AUTOSAR XML (schema 4-2-2)
package /pkg_intf
  sender receiver interface if_voltage
    data voltage: type=adt_voltage
  sender receiver interface if_duty
    data duty: type=adt_duty
package /pkg_led
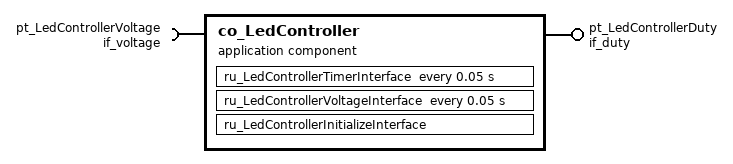
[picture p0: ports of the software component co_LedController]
  application sw component type co_LedController
    provide port pt_LedControllerDuty: provided-interface=if_duty
    require port pt_LedControllerVoltage: required-interface=if_voltage
    behavior IB_co_LedController: data-type-mapping=DTMS_DataTypeMappingSet, handle-termination-and-restart=NO-SUPPORT
      timing event TE_50ms: start-on-event=ru_LedControllerTimerInterface, period=0.05
      timing event TE_50ms: start-on-event=ru_LedControllerVoltageInterface, period=0.05
      runnable ru_LedControllerTimerInterface
        data-read-access:
          access calcDuty
        data-write-access:
          access dsp_LedControllerDuty: accessed-variable=pt_LedControllerDuty.duty
      runnable ru_LedControllerInitializeInterface
        data-write-access:
          access initDuty
      runnable ru_LedControllerVoltageInterface
        data-read-access:
          access drp_LedControllerVoltage: accessed-variable=pt_LedControllerVoltage.voltage
        data-write-access:
          access op_duty
package /pkg_types
  unit Unit_None: display-name=Description for Unit_None
  impl type idt_duty: category=VALUE, base-type=float32
  impl type idt_voltage: category=VALUE, base-type=float32
  app type adt_duty: category=VALUE
  app type adt_voltage: category=VALUE
  range dc_duty: phys -1..1
  range dc_pwm: phys 0..32768
package /Cla_CommonUnits
  unit min: display-name=time: minutes, factor-si-to-unit=60
  13 x physical dimension:
    radpss: time-exp=-1
    radps: time-exp=-1
    rad: length-exp=0
    W: time-exp=-1
    J: length-exp=1
    N: mass-exp=1
    mpss: time-exp=-1
    mps: length-exp=1, time-exp=-1
    Nm: length-exp=1
    kgpm3: length-exp=-3, mass-exp=1
    kgps: mass-exp=1, time-exp=-1
    kgm2: length-exp=2, mass-exp=1
    m2: length-exp=2
  unit deg: display-name=Angle: Degrees, factor-si-to-unit=180
  unit rpm: display-name=Angular Speed: rev/min, factor-si-to-unit=30
  physical dimension WpK: temperature-exp=-1
  physical dimension JpK: temperature-exp=-1
  unit Nms: display-name=Damping: N-m/(rad/s)
  physical dimension m3: length-exp=3
  physical dimension V: current-exp=-1
  unit kW: display-name=Power: kilowatts, factor-si-to-unit=1000
  unit MW: display-name=Power: Megawatts, factor-si-to-unit=1000
  physical dimension Hz: time-exp=-1
  physical dimension Wpm2K: length-exp=-2, temperature-exp=-1
  unit mpspdegC: display-name=mps / degC - for ambient correction in ThermalModule
  unit degC: display-name=Temperature: Deg C
  physical dimension JpKgK: mass-exp=-1, temperature-exp=-1
  unit rev: display-name=Angular displacement: Revolutions, factor-si-to-unit=360
  physical dimension m3ps: length-exp=3, time-exp=-1
  physical dimension Pa: length-exp=-2
  unit kPa: display-name=Pressure or stress: Kilo Pascal, factor-si-to-unit=1000
  unit MPA: display-name=Pressure or stress: Mega Pascal, factor-si-to-unit=1000
  unit ms: display-name=milli second, factor-si-to-unit=1000
package /SIUnits
  7 x unit:
    m: display-name=metre
    s: display-name=second
    kg: display-name=kilogram
    mol: display-name=amount of chemical substance
    K: display-name=temperature
    A: display-name=current
    cd: display-name=luminous intensity
  physical dimension nounit: length-exp=0
package /pkg_types
  unit Unit_None: display-name=Description for Unit_None
package /pkg_types
  range dc_duty: phys -1..1
  range dc_pwm: phys 0..32768
